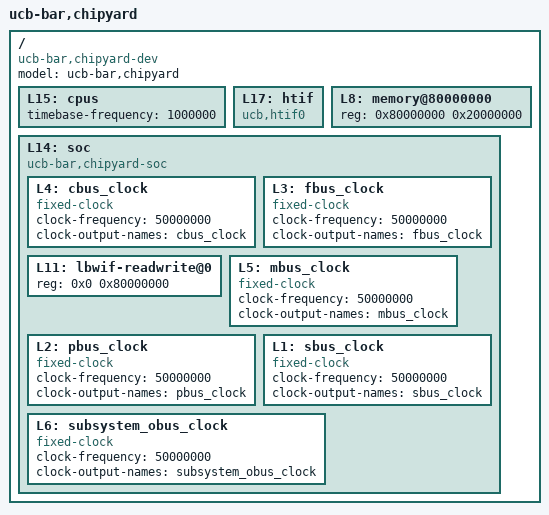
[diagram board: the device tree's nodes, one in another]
/dts-v1/;

/ {
	#address-cells = <1>;
	#size-cells = <1>;
	compatible = "ucb-bar,chipyard-dev";
	model = "ucb-bar,chipyard";
	L15: cpus {
		#address-cells = <1>;
		#size-cells = <0>;
		timebase-frequency = <1000000>;
	};
	L17: htif {
		compatible = "ucb,htif0";
	};
	L8: memory@80000000 {
		device_type = "memory";
		reg = <0x80000000 0x20000000>;
	};
	L14: soc {
		#address-cells = <1>;
		#size-cells = <1>;
		compatible = "ucb-bar,chipyard-soc", "simple-bus";
		ranges;
		L4: cbus_clock {
			#clock-cells = <0>;
			clock-frequency = <50000000>;
			clock-output-names = "cbus_clock";
			compatible = "fixed-clock";
		};
		L3: fbus_clock {
			#clock-cells = <0>;
			clock-frequency = <50000000>;
			clock-output-names = "fbus_clock";
			compatible = "fixed-clock";
		};
		L11: lbwif-readwrite@0 {
			reg = <0x0 0x80000000>;
		};
		L5: mbus_clock {
			#clock-cells = <0>;
			clock-frequency = <50000000>;
			clock-output-names = "mbus_clock";
			compatible = "fixed-clock";
		};
		L2: pbus_clock {
			#clock-cells = <0>;
			clock-frequency = <50000000>;
			clock-output-names = "pbus_clock";
			compatible = "fixed-clock";
		};
		L1: sbus_clock {
			#clock-cells = <0>;
			clock-frequency = <50000000>;
			clock-output-names = "sbus_clock";
			compatible = "fixed-clock";
		};
		L6: subsystem_obus_clock {
			#clock-cells = <0>;
			clock-frequency = <50000000>;
			clock-output-names = "subsystem_obus_clock";
			compatible = "fixed-clock";
		};
	};
};
